# PRM_IRQ register map
Vendor: Texas Instruments
Peripheral module from a debugger description file (folder am437x).
Registers are 32-bit, access per field, no defined reset value unless marked. A register's access mark holds for its fields unless they carry their own. Offsets are as the file gives them; lines under a group give offsets from that group; [hi:lo] are bit positions; {n}, {i} and the like mark numbered series; 'fields as' and 'values as' point back to an identical list; <NAME> marks a mode.

## PRM_IRQ
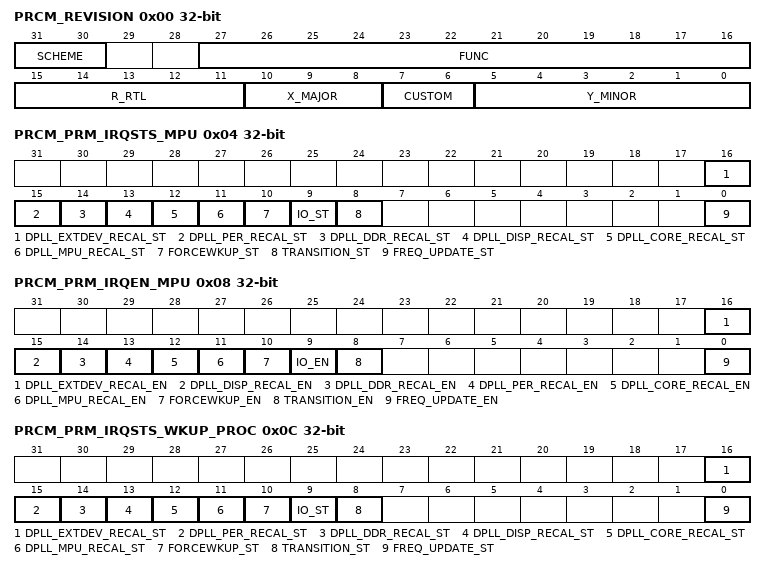
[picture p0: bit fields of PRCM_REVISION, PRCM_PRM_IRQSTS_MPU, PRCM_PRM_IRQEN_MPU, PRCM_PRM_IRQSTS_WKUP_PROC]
0x00 PRCM_REVISION ro — This register contains the IP revision code for the PRCM
  [31:30] SCHEME — Used to distinguish between old scheme and current.
    1=en_2_0x1 (Highlander 0.8 scheme); 0=en_1_0x0 (Legacy ASP or WTBU scheme)
  [27:16] FUNC — Function indicates a software compatible module family.
  [15:11] R_RTL — RTL Version (R), maintained by IP design owner.
  [10:8] X_MAJOR — Major Revision (X), maintained by IP specification owner.
    1=en_2_0x1 (Reserved); 0=en_1_0x0 (Reserved)
  [7:6] CUSTOM — Indicates a special version for a particular device.
    0=en_1_0x0 (Non custom (standard) revision)
  [5:0] Y_MINOR — Minor Revision (Y), maintained by IP specification owner.
    0=en_1_0x0 (ES1.0 and similar versions)
0x04 PRCM_PRM_IRQSTS_MPU — This register provides status on MPU interrupt events. An event is logged whether interrupt generation for the event is enabled or not. SW is required to clear a set bit by writing a '1' into the bit-position to be cleared.
  [16] DPLL_EXTDEV_RECAL_ST rw — interrupt status for extdev dpll recaliberation
    1=en_2_0x1 (ENAbles dpll recaliberation); 0=en_1_0x0 (Disables dpll recaliberation)
  [15] DPLL_PER_RECAL_ST rw — interrupt status for usb dpll recaliberation
    values as DPLL_EXTDEV_RECAL_ST
  [14] DPLL_DDR_RECAL_ST rw — interrupt status for ddr dpll recaliberation
    values as DPLL_EXTDEV_RECAL_ST
  [13] DPLL_DISP_RECAL_ST rw — interrupt status for disp dpll recaliberation
    values as DPLL_EXTDEV_RECAL_ST
  [12] DPLL_CORE_RECAL_ST rw — interrupt status for core dpll recaliberation
    values as DPLL_EXTDEV_RECAL_ST
  [11] DPLL_MPU_RECAL_ST rw — interrupt status for mpu dpll recaliberation
    values as DPLL_EXTDEV_RECAL_ST
  [10] FORCEWKUP_ST rw — Software supervised wakeup completed event interrupt status
    1=en_2_0x1 (Interrupt is pending); 0=en_1_0x0 (No interrupt)
  [9] IO_ST rw — IO pad event interrupt status.
    1=en_2_0x1 (Interrupt is pending); 0=en_1_0x0 (No interrupt)
  [8] TRANSITION_ST rw — Software supervised transition completed event interrupt status (any domain)
    1=en_2_0x1 (Interrupt is pending); 0=en_1_0x0 (No interrupt)
  [0] FREQ_UPDATE_ST rw — Frequency Update interrupt status.
    1=en_2_0x1 (Interrupt is pending); 0=en_1_0x0 (No interrupt)
0x08 PRCM_PRM_IRQEN_MPU — This register is used to enable and disable events used to trigger MPU interrupt activation.
  [16] DPLL_EXTDEV_RECAL_EN rw — Interrupt enable for extdev dpll recaliberation
    values as PRCM_PRM_IRQSTS_MPU.DPLL_EXTDEV_RECAL_ST
  [15] DPLL_DISP_RECAL_EN rw — Interrupt enable for disp dpll recaliberation
    values as PRCM_PRM_IRQSTS_MPU.DPLL_EXTDEV_RECAL_ST
  [14] DPLL_DDR_RECAL_EN rw — Interrupt enable for ddr dpll recaliberation
    values as PRCM_PRM_IRQSTS_MPU.DPLL_EXTDEV_RECAL_ST
  [13] DPLL_PER_RECAL_EN rw — Interrupt enable for usb dpll recaliberation
    values as PRCM_PRM_IRQSTS_MPU.DPLL_EXTDEV_RECAL_ST
  [12] DPLL_CORE_RECAL_EN rw — Interrupt enable for core dpll recaliberation
    values as PRCM_PRM_IRQSTS_MPU.DPLL_EXTDEV_RECAL_ST
  [11] DPLL_MPU_RECAL_EN rw — Interrupt enable for mpu dpll recaliberation
    values as PRCM_PRM_IRQSTS_MPU.DPLL_EXTDEV_RECAL_ST
  [10] FORCEWKUP_EN rw — Software supervised Froce Wakeup completed event interrupt enable
    1=en_2_0x1 (Interrupt is enabled); 0=en_1_0x0 (Interrupt is masked)
  [9] IO_EN rw — IO pad event interrupt enable
    values as FORCEWKUP_EN
  [8] TRANSITION_EN rw — Software supervised transition completed event interrupt enable (any domain)
    values as FORCEWKUP_EN
  [0] FREQ_UPDATE_EN rw — Frequency Update interrupt enable.
    values as FORCEWKUP_EN
0x0C PRCM_PRM_IRQSTS_WKUP_PROC — This register provides status on Wakeup Processor interrupt events. An event is logged whether interrupt generation for the event is enabled or not. SW is required to clear a set bit by writing a '1' into the bit-position to be cleared.
  fields as PRCM_PRM_IRQSTS_MPU
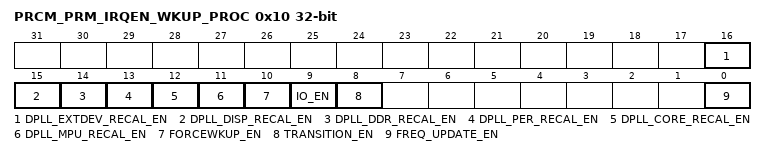
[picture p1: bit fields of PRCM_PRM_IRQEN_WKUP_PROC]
0x10 PRCM_PRM_IRQEN_WKUP_PROC — This register is used to enable and disable events used to trigger Wakeup Processor interrupt activation.
  fields as PRCM_PRM_IRQEN_MPU
